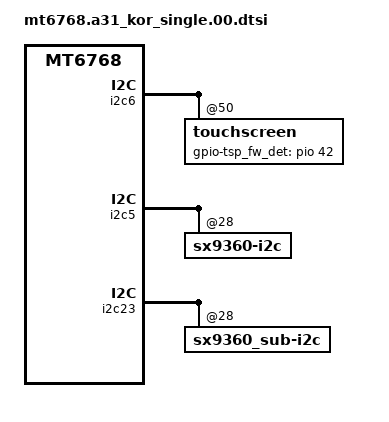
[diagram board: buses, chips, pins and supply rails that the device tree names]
/* 
 * Generated by Samsung 
 * If these files should be changed, then please make a sync with MTK
*/

#include "../../mediatek/k68v1_64_titan/gpio02_a31_kor.dtsi"
#include "mt6768-a31_common.dtsi"
#include "mt6768-a31_camera_01.dtsi"
#include "mt6768-a31_sensor_grip_01.dtsi"
#include "s2mu106_motor.dtsi"
#include "mt6768-a31_input_common.dtsi"
#include "mt6768-a31_pm_common.dtsi"
#include "mt6768-a31_audio_common.dtsi"

/* Add Samsung configuration over here */

&msdc1 {
	cd_level = /bits/ 8 <MSDC_CD_LOW>;
};

&i2c6 {
	touchscreen@50 {
		pinctrl-0 = <&tsp_irq_active &fw_det_active>;
		imagis,gpio-tsp_fw_det = <&pio 42 0>;
	};
};

&pio {
	fw_det_active: fw_det_active {
		pins_cmd_dat {
			pinmux = <PINMUX_GPIO42__FUNC_GPIO42>;
			bias-disable;
			input-enable;
			slew-rate = <0>;
		};
	};
};

&i2c5 {
	sx9360-i2c@28 {
		sx9360,reggnrlctrl2_reg = <0x19>; /* scanperiod: 51ms */
		sx9360,refresolution_reg = <0x0F>; /* same as resolution_reg */
		sx9360,refagainfreq_reg = <0x36>; /* same as againfreq_reg */
		sx9360,resolution_reg = <0x0F>; /* resolution : 1024 */
		sx9360,againfreq_reg = <0x11>; /* 0x25 - freq : 200 kHz, again : +/-2.25 pF */
		sx9360,refgainrawfilt_reg = <0x22>; /* reference phase gain: x8, rawfilt : 1-1/4 */
		sx9360,gainrawfilt_reg = <0x0A>; /* rawfilter : 1-1/4, gain : x1 */
		sx9360,regproxctrl3_reg = <0x0A>; /* 0x44 - avgposfilt: 1/64, avgnegfilt: 1/2 */
		sx9360,hyst_reg = <0x15>; /* hysteresis : +/-6 %, debouncer : 2 samples */
		sx9360,proxthresh_reg = <0x14>; /* 0x46 - threshhold : 200 */
		sx9360,hallic_detect = <0>;
		sx9360,hallic_cert_detect = <0>;
	};
};

&i2c23 {
	sx9360_sub-i2c@28 {
		sx9360,refresolution_reg = <0x0F>; /* same as resolution_reg */
		sx9360,refagainfreq_reg = <0x36>; /* same as againfreq_reg */
		sx9360,resolution_reg = <0x0F>; /* resolution : 1024 */
		sx9360,againfreq_reg = <0x15>; /* 0x25 - freq : 125 kHz, again : +/-2.25 pF */
		sx9360,refgainrawfilt_reg = <0x22>; /* same as gainrawfilt_reg */
		sx9360,gainrawfilt_reg = <0x12>; /* 0x41 - rawfilter : 1-1/4, gain : x1 */
		sx9360,hyst_reg = <0x15>; /* hysteresis : +/-6 %, debouncer : 2 samples */
		sx9360,proxthresh_reg = <0x1F>; /* 0X46 - threshhold : 612 */
		sx9360_sub,hallic_detect = <0>;
		sx9360_sub,hallic_cert_detect = <0>;
	};
};


/*End of this file, DO NOT ADD ANYTHING HERE*/
